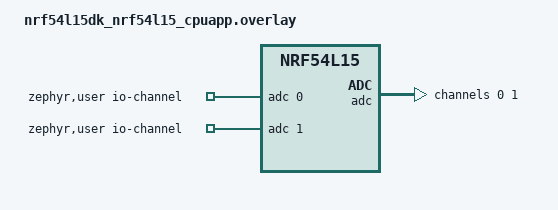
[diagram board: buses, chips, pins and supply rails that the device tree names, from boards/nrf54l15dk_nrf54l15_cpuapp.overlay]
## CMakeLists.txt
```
cmake_minimum_required(VERSION 3.20.0)
find_package(Zephyr REQUIRED HINTS $ENV{ZEPHYR_BASE})
project(m1_logger)

target_sources(app PRIVATE src/main.c)
```

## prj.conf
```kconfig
# M1 bench logger: raw TMR bridge -> SAADC -> CSV over UART console
CONFIG_ADC=y
CONFIG_SERIAL=y
CONFIG_CONSOLE=y
CONFIG_UART_CONSOLE=y
```

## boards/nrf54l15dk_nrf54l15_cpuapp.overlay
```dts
/* Two SINGLE-ENDED SAADC channels for one AAT003-10E-EVB01.
 *
 * Reality check vs the original differential plan: the EVB01 breakout
 * exposes single-ended half-bridge outputs only (card: Pin2=Cos, Pin5=Sin,
 * Pins 3/4=GND, Pins 1/6=Vdd) - there are no SIN-/COS- pins. Outputs sit
 * at mid-rail (~Vdd/2) with the signal swing on top, so:
 *
 * ch0: AIN0 (P1.04) = Sin      ch1: AIN2 (P1.06) = Cos
 * gain 1/4 against the 0.9 V internal reference -> 0..3.6 V input range,
 * which fits the ~1.65 V +/- 0.33 V signal with margin (0.88 mV/LSB).
 *
 * 40 us acquisition time kept: AAT003 source impedance is ~40 kOhm and
 * the SAADC sample cap needs the long setting to settle through it.
 */

#include <dt-bindings/adc/adc.h>
#include <zephyr/dt-bindings/adc/nrf-saadc.h>

/ {
	zephyr,user {
		io-channels = <&adc 0>, <&adc 1>;
	};
};

&adc {
	status = "okay";
	#address-cells = <1>;
	#size-cells = <0>;

	channel@0 {
		reg = <0>;
		zephyr,gain = "ADC_GAIN_1_4";
		zephyr,reference = "ADC_REF_INTERNAL";
		zephyr,acquisition-time = <ADC_ACQ_TIME(ADC_ACQ_TIME_MICROSECONDS, 40)>;
		zephyr,input-positive = <NRF_SAADC_AIN0>;
		zephyr,resolution = <12>;
	};

	channel@1 {
		reg = <1>;
		zephyr,gain = "ADC_GAIN_1_4";
		zephyr,reference = "ADC_REF_INTERNAL";
		zephyr,acquisition-time = <ADC_ACQ_TIME(ADC_ACQ_TIME_MICROSECONDS, 40)>;
		zephyr,input-positive = <NRF_SAADC_AIN2>;
		zephyr,resolution = <12>;
	};
};
```

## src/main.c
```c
/* M1 bench logger.
 *
 * Streams two differential SAADC channels (sin/cos TMR bridge pair)
 * as CSV over the UART console:
 *
 *   t_ms,ch0_raw,ch0_mv,ch1_raw,ch1_mv
 *
 * SAMPLE_HZ is capped by console bandwidth: ~30 bytes/line at
 * 115200 baud tops out near 380 lines/s. 200 Hz default leaves
 * headroom; gap characterization is static/slow-slide data anyway.
 * For flick-speed captures later, raise the VCOM baud and this rate.
 */

#include <zephyr/kernel.h>
#include <zephyr/drivers/adc.h>
#include <zephyr/sys/printk.h>

#define SAMPLE_HZ 200

static const struct adc_dt_spec channels[] = {
	ADC_DT_SPEC_GET_BY_IDX(DT_PATH(zephyr_user), 0),
	ADC_DT_SPEC_GET_BY_IDX(DT_PATH(zephyr_user), 1),
};

int main(void)
{
	int16_t buf;
	struct adc_sequence sequence = {
		.buffer = &buf,
		.buffer_size = sizeof(buf),
	};

	for (size_t i = 0; i < ARRAY_SIZE(channels); i++) {
		if (!adc_is_ready_dt(&channels[i])) {
			printk("# ADC %s not ready\n", channels[i].dev->name);
			return 0;
		}
		int err = adc_channel_setup_dt(&channels[i]);
		if (err) {
			printk("# channel %d setup failed (%d)\n", (int)i, err);
			return 0;
		}
	}

	printk("# m1_logger: %d Hz, single-ended, 12-bit\n", SAMPLE_HZ);
	printk("t_ms,ch0_raw,ch0_mv,ch1_raw,ch1_mv\n");

	while (1) {
		int64_t t = k_uptime_get();
		int32_t raw[ARRAY_SIZE(channels)];
		int32_t mv[ARRAY_SIZE(channels)];

		for (size_t i = 0; i < ARRAY_SIZE(channels); i++) {
			adc_sequence_init_dt(&channels[i], &sequence);
			int err = adc_read_dt(&channels[i], &sequence);
			if (err) {
				printk("# read ch%d failed (%d)\n", (int)i, err);
				raw[i] = 0;
				mv[i] = 0;
				continue;
			}
			raw[i] = buf;
			mv[i] = buf;
			adc_raw_to_millivolts_dt(&channels[i], &mv[i]);
		}

		printk("%lld,%d,%d,%d,%d\n", t, raw[0], mv[0], raw[1], mv[1]);
		k_sleep(K_USEC(1000000 / SAMPLE_HZ));
	}
	return 0;
}
```
